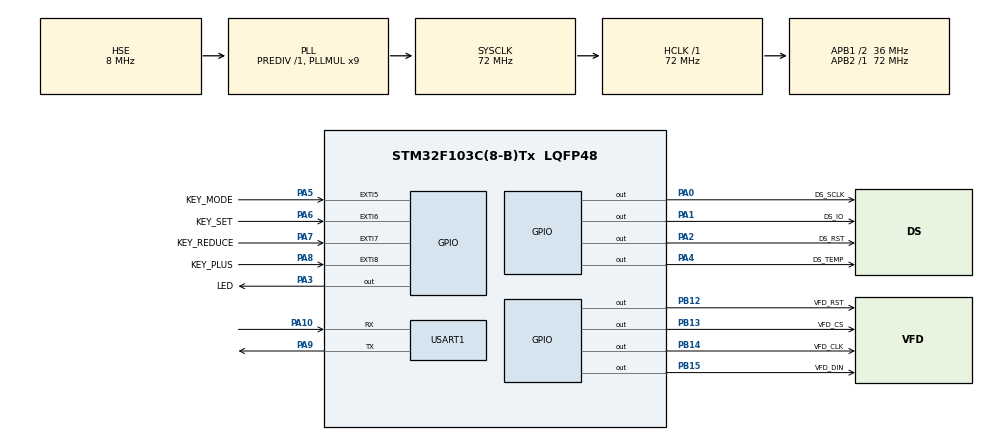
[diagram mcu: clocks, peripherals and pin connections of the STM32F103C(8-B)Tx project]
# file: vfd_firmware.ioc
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Mcu.Family=STM32F1
Mcu.Name=STM32F103C(8-B)Tx
Mcu.Package=LQFP48
NVIC.EXTI9_5_IRQn=true\:0\:0\:false\:false\:true\:true\:true\:true
NVIC.PriorityGroup=NVIC_PRIORITYGROUP_4
PA0-WKUP.GPIO_Label=DS_SCLK
PA0-WKUP.Signal=GPIO_Output
PA1.GPIO_Label=DS_IO
PA1.Signal=GPIO_Output
PA10.Mode=Asynchronous
PA10.Signal=USART1_RX
PA13.Mode=Serial_Wire
PA13.Signal=SYS_JTMS-SWDIO
PA14.Mode=Serial_Wire
PA14.Signal=SYS_JTCK-SWCLK
PA2.GPIO_Label=DS_RST
PA2.Signal=GPIO_Output
PA3.GPIO_Label=LED
PA3.Signal=GPIO_Output
PA4.GPIO_Label=DS_TEMP
PA4.Signal=GPIO_Output
PA5.GPIO_Label=KEY_MODE
PA5.GPIO_ModeDefaultEXTI=GPIO_MODE_IT_RISING
PA5.GPIO_PuPd=GPIO_PULLUP
PA5.Signal=GPXTI5
PA6.GPIO_Label=KEY_SET
PA6.GPIO_ModeDefaultEXTI=GPIO_MODE_IT_RISING
PA6.GPIO_PuPd=GPIO_PULLUP
PA6.Signal=GPXTI6
PA7.GPIO_Label=KEY_REDUCE
PA7.GPIO_PuPd=GPIO_PULLUP
PA7.Signal=GPXTI7
PA8.GPIO_Label=KEY_PLUS
PA8.GPIO_PuPd=GPIO_PULLUP
PA8.Signal=GPXTI8
PA9.Mode=Asynchronous
PA9.Signal=USART1_TX
PB12.GPIO_Label=VFD_RST
PB12.Signal=GPIO_Output
PB13.GPIO_Label=VFD_CS
PB13.Signal=GPIO_Output
PB14.GPIO_Label=VFD_CLK
PB14.Signal=GPIO_Output
PB15.GPIO_Label=VFD_DIN
PB15.Signal=GPIO_Output
PC14-OSC32_IN.Mode=LSE-External-Oscillator
PC14-OSC32_IN.Signal=RCC_OSC32_IN
PC15-OSC32_OUT.Mode=LSE-External-Oscillator
PC15-OSC32_OUT.Signal=RCC_OSC32_OUT
PD0-OSC_IN.Mode=HSE-External-Oscillator
PD0-OSC_IN.Signal=RCC_OSC_IN
PD1-OSC_OUT.Mode=HSE-External-Oscillator
PD1-OSC_OUT.Signal=RCC_OSC_OUT
ProjectManager.HeapSize=0x200
ProjectManager.StackSize=0x400
ProjectManager.TargetToolchain=STM32CubeIDE
RCC.AHBFreq_Value=72000000
RCC.APB1CLKDivider=RCC_HCLK_DIV2
RCC.APB1Freq_Value=36000000
RCC.APB1TimFreq_Value=72000000
RCC.APB2Freq_Value=72000000
RCC.APB2TimFreq_Value=72000000
RCC.HCLKFreq_Value=72000000
RCC.PLLMUL=RCC_PLL_MUL9
RCC.PLLSourceVirtual=RCC_PLLSOURCE_HSE
RCC.SYSCLKFreq_VALUE=72000000
RCC.SYSCLKSource=RCC_SYSCLKSOURCE_PLLCLK
RCC.USBFreq_Value=72000000
TIM2.AutoReloadPreload=TIM_AUTORELOAD_PRELOAD_DISABLE
TIM2.Prescaler=71
USART1.VirtualMode=VM_ASYNC
VP_TIM2_VS_ClockSourceINT.Mode=Internal
board=custom

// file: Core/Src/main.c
/* USER CODE BEGIN Header */
/**
  ******************************************************************************
  * @file           : main.c
  * @brief          : Main program body
  ******************************************************************************
  * @attention
  *
  * Copyright (c) 2022 STMicroelectronics.
  * All rights reserved.
  *
  * This software is licensed under terms that can be found in the LICENSE file
  * in the root directory of this software component.
  * If no LICENSE file comes with this software, it is provided AS-IS.
  *
  ******************************************************************************
  */
/* USER CODE END Header */
#include "main.h"
#include "tim.h"
#include "usart.h"
#include "gpio.h"

/* USER CODE BEGIN Includes */
#include "logic_service.h"
/* USER CODE END Includes */

void SystemClock_Config(void);

int main(void) {

    /* MCU Configuration--------------------------------------------------------*/

    /* Reset of all peripherals, Initializes the Flash interface and the Systick. */
    HAL_Init();

    /* Configure the system clock */
    SystemClock_Config();

    /* Initialize all configured peripherals */
    MX_GPIO_Init();
    MX_TIM2_Init();
    MX_USART1_UART_Init();

    /* USER CODE BEGIN 2 */
    VFD_init();
    SER_Init();
    //关闭LED的指示灯
    HAL_GPIO_WritePin(GPIOA, LED_Pin, GPIO_PIN_SET);
    /* USER CODE END 2 */

    /* Infinite loop */

    /* USER CODE BEGIN WHILE */
    while (1) {
        SER_LOOP();
        /* USER CODE END WHILE */

    }
}

void SystemClock_Config(void) {
    RCC_OscInitTypeDef RCC_OscInitStruct = {0};
    RCC_ClkInitTypeDef RCC_ClkInitStruct = {0};

    /** Initializes the RCC Oscillators according to the specified parameters
    * in the RCC_OscInitTypeDef structure.
    */
    RCC_OscInitStruct.OscillatorType = RCC_OSCILLATORTYPE_HSE;
    RCC_OscInitStruct.HSEState = RCC_HSE_ON;
    RCC_OscInitStruct.HSEPredivValue = RCC_HSE_PREDIV_DIV1;
    RCC_OscInitStruct.HSIState = RCC_HSI_ON;
    RCC_OscInitStruct.PLL.PLLState = RCC_PLL_ON;
    RCC_OscInitStruct.PLL.PLLSource = RCC_PLLSOURCE_HSE;
    RCC_OscInitStruct.PLL.PLLMUL = RCC_PLL_MUL9;
    if (HAL_RCC_OscConfig(&RCC_OscInitStruct) != HAL_OK) {
        Error_Handler();
    }

    /** Initializes the CPU, AHB and APB buses clocks
    */
    RCC_ClkInitStruct.ClockType = RCC_CLOCKTYPE_HCLK | RCC_CLOCKTYPE_SYSCLK
                                  | RCC_CLOCKTYPE_PCLK1 | RCC_CLOCKTYPE_PCLK2;
    RCC_ClkInitStruct.SYSCLKSource = RCC_SYSCLKSOURCE_PLLCLK;
    RCC_ClkInitStruct.AHBCLKDivider = RCC_SYSCLK_DIV1;
    RCC_ClkInitStruct.APB1CLKDivider = RCC_HCLK_DIV2;
    RCC_ClkInitStruct.APB2CLKDivider = RCC_HCLK_DIV1;

    if (HAL_RCC_ClockConfig(&RCC_ClkInitStruct, FLASH_LATENCY_2) != HAL_OK) {
        Error_Handler();
    }
}

/* USER CODE BEGIN 4 */
int __io_putchar(int ch) {
    HAL_UART_Transmit(&huart1, (uint8_t *) &ch, 1, 0xFFFF);
    return ch;
}
/* USER CODE END 4 */

void Error_Handler(void) {
    /* USER CODE BEGIN Error_Handler_Debug */
    /* User can add his own implementation to report the HAL error return state */
    __disable_irq();
    while (1) {
        HAL_GPIO_TogglePin(GPIOA, LED_Pin);
        HAL_Delay(500);
        printf("ERROR\n");
    }
    /* USER CODE END Error_Handler_Debug */
}
